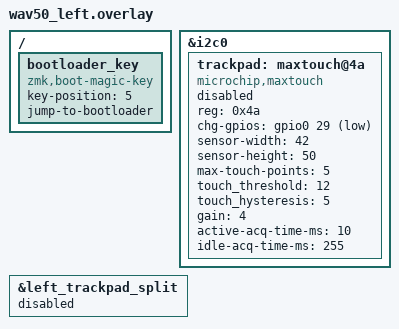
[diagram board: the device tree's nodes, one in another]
#include "wav50.dtsi"

/ {
    bootloader_key: bootloader_key {
        compatible = "zmk,boot-magic-key";
        key-position = <5>;
        jump-to-bootloader;
    };
};

&i2c0 {
    status = "okay";

    trackpad: maxtouch@4a {
        compatible = "microchip,maxtouch";
        status = "disabled";
        reg = <0x4a>;
        chg-gpios = <&gpio0 29 (GPIO_ACTIVE_LOW | GPIO_PULL_UP)>;
        sensor-width = <42>;
        sensor-height = <50>;
        max-touch-points = <5>;
        touch_threshold = <12>;
        touch_hysteresis = <5>;
        gain = <4>;
        active-acq-time-ms = <10>;
        idle-acq-time-ms = <255>;
    };
};

&left_trackpad_split {
    status = "disabled";
};
